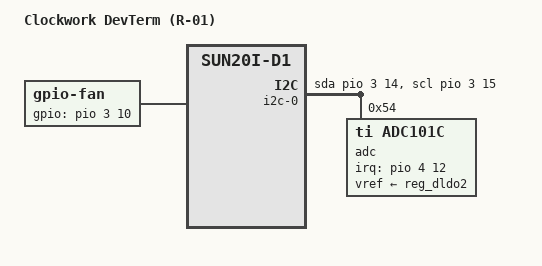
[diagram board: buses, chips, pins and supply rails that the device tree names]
// SPDX-License-Identifier: (GPL-2.0+ or MIT)
// Copyright (C) 2022 Samuel Holland <samuel@sholland.org>

#include "sun20i-d1-clockworkpi-v3.14.dts"

/ {
	model = "Clockwork DevTerm (R-01)";
	compatible = "clockwork,r-01-devterm-v3.14",
		     "clockwork,r-01-clockworkpi-v3.14",
		     "allwinner,sun20i-d1";

	fan {
		compatible = "gpio-fan";
		gpios = <&pio 3 10 GPIO_ACTIVE_HIGH>; /* PD10/GPIO41 */
		gpio-fan,speed-map = <0    0>,
				     <6000 1>;
		#cooling-cells = <2>;
	};

	i2c-0 {
		compatible = "i2c-gpio";
		sda-gpios = <&pio 3 14 (GPIO_ACTIVE_HIGH|GPIO_OPEN_DRAIN)>; /* PD14/GPIO44 */
		scl-gpios = <&pio 3 15 (GPIO_ACTIVE_HIGH|GPIO_OPEN_DRAIN)>; /* PD15/GPIO45 */
		#address-cells = <1>;
		#size-cells = <0>;

		adc@54 {
			compatible = "ti,adc101c";
			reg = <0x54>;
			interrupt-parent = <&pio>;
			interrupts = <4 12 IRQ_TYPE_LEVEL_LOW>; /* PE12/GPIO35 */
			vref-supply = <&reg_dldo2>;
			#io-channel-cells = <1>;
		};
	};
};
